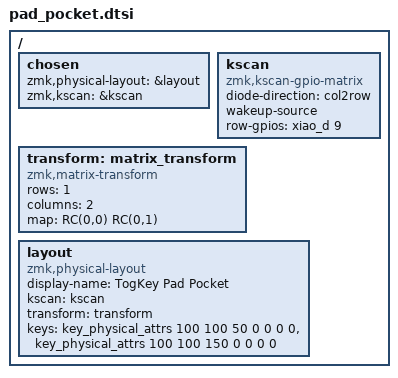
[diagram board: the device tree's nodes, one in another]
#include <physical_layouts.dtsi>
#include <dt-bindings/zmk/matrix_transform.h>

/ {
    chosen {
        zmk,physical-layout = &layout;
        zmk,kscan = &kscan;
    };

    kscan: kscan {
        compatible = "zmk,kscan-gpio-matrix";
        diode-direction = "col2row";
        wakeup-source;


        row-gpios = <&xiao_d 9 (GPIO_ACTIVE_HIGH | GPIO_PULL_DOWN)>;

    };

    transform: matrix_transform {
        compatible = "zmk,matrix-transform";
        rows = <1>;
        columns = <2>;

        map = <
        //   Key 1 | Key 2
            RC(0,0) RC(0,1)
        >;

    };
    
    layout: layout {
        compatible = "zmk,physical-layout";
        display-name = "TogKey Pad Pocket";
        kscan = <&kscan>;
        transform = <&transform>;

        keys  //                     w   h    x    y     rot    rx    ry
            = <&key_physical_attrs 100 100   50    0       0     0     0>
            , <&key_physical_attrs 100 100  150    0       0     0     0>
            ;
    };
};
